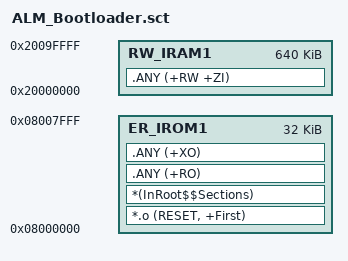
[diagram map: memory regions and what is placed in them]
; *************************************************************
; *** Scatter-Loading Description File: ALM_CIC_Bootloader        ***
; *** Bootloader region: 0x08000000 ~ 0x08007FFF (32 KB)       ***
; *** App region (handled by ALM_CIC_APP): 0x08008000 onwards      ***
; *************************************************************

LR_IROM1 0x08000000 0x00008000  {    ; load region size_region
  ER_IROM1 0x08000000 0x00008000  {  ; load address = execution address
   *.o (RESET, +First)
   *(InRoot$$Sections)
   .ANY (+RO)
   .ANY (+XO)
  }
  RW_IRAM1 0x20000000 0x000A0000  {  ; full 640 KB SRAM (SRAM1+SRAM2+SRAM3)
   .ANY (+RW +ZI)
  }
}
